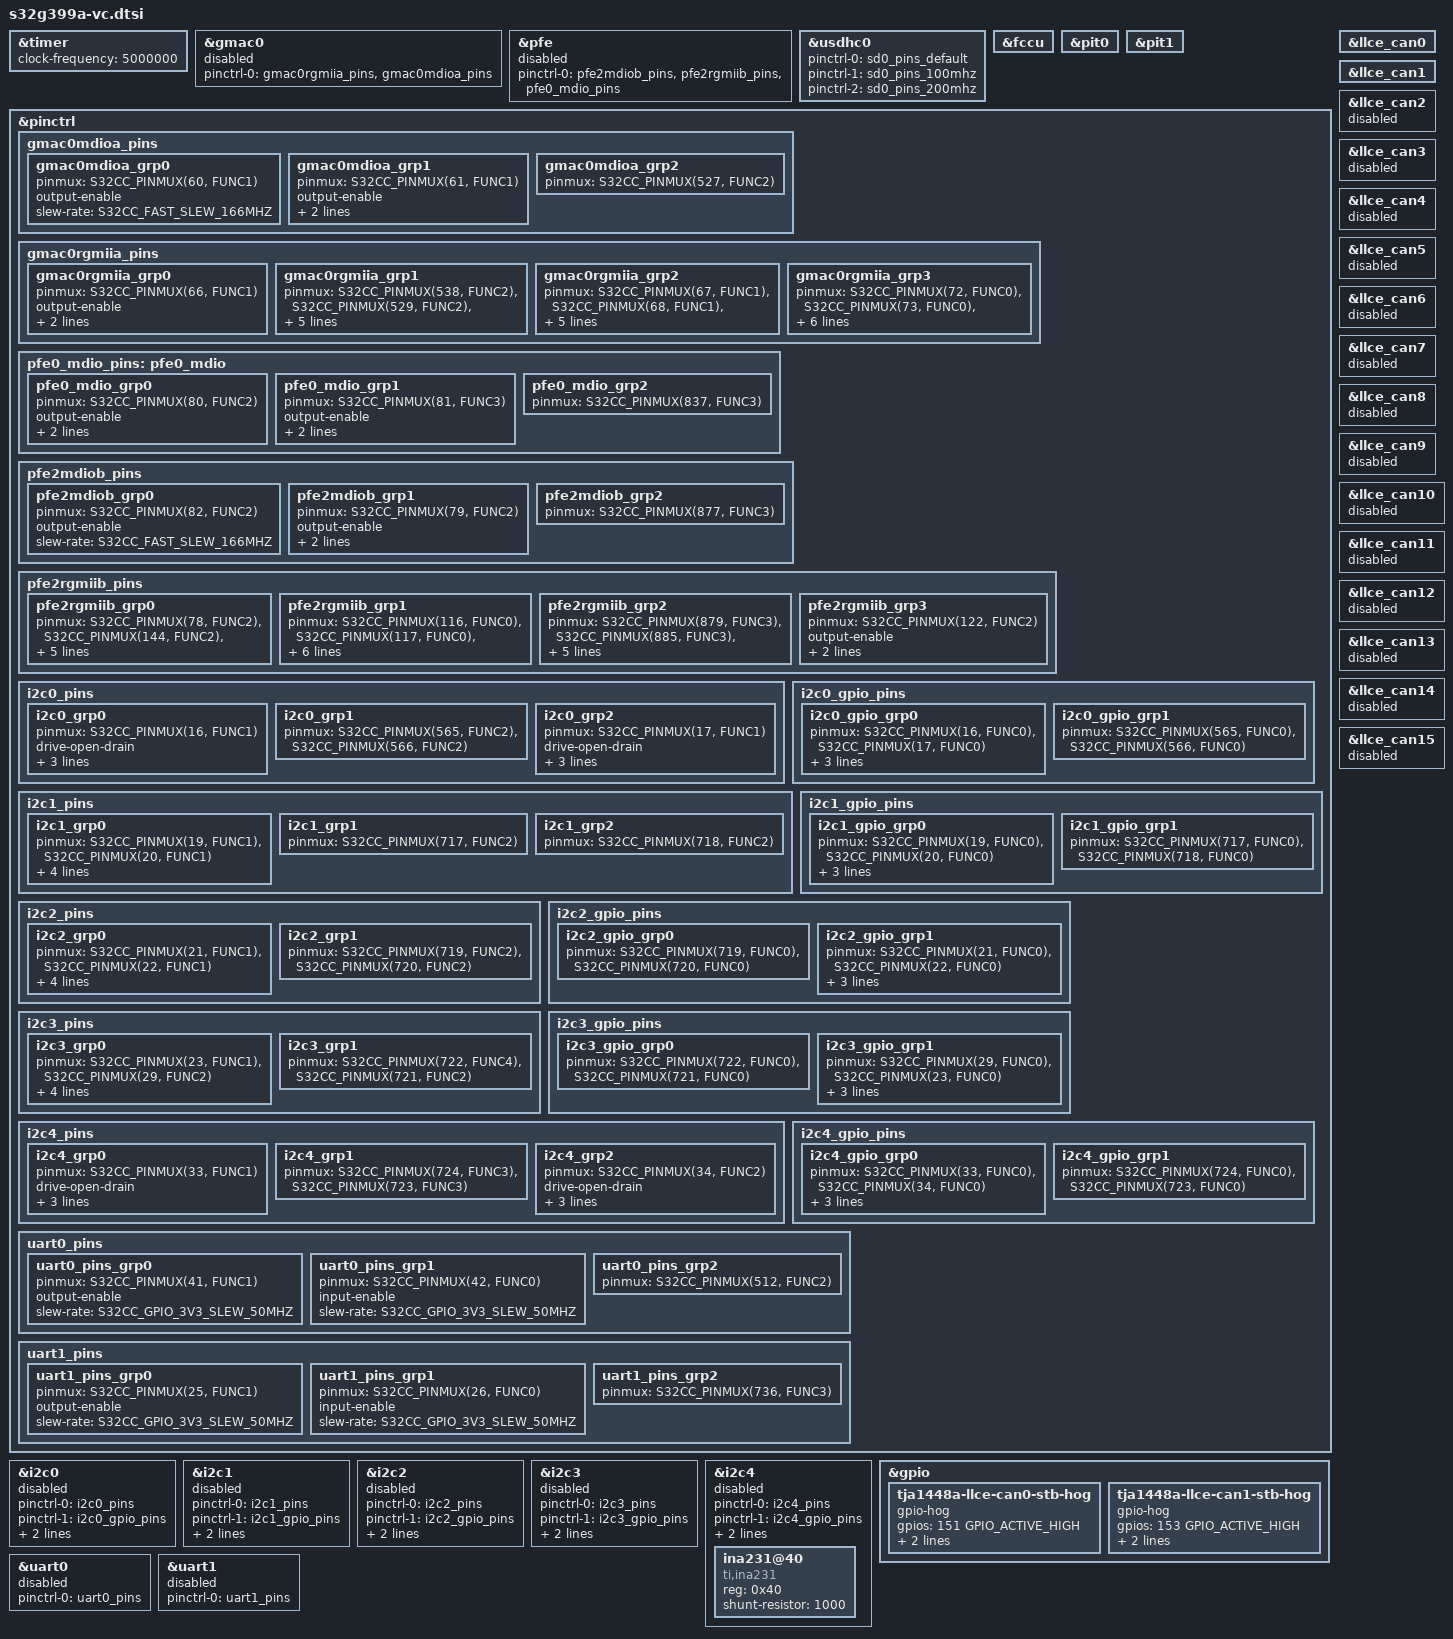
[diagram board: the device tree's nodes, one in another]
// SPDX-License-Identifier: GPL-2.0-or-later OR BSD-3-Clause
/*
 * Copyright 2024 NXP
 */

#include <dt-bindings/gpio/gpio.h>
#include "s32g3.dtsi"
#include "s32g-nxp-flash-macronix.dtsi"

&timer {
	clock-frequency = <5000000>;
};

&gmac0 {
	status = "disabled";
	pinctrl-names = "default";
	pinctrl-0 = <&gmac0rgmiia_pins>, <&gmac0mdioa_pins>;
};

&pfe {
	status = "disabled";
	pinctrl-names = "default";
	pinctrl-0 = <&pfe2mdiob_pins>, <&pfe2rgmiib_pins>, <&pfe0_mdio_pins>;
};

&usdhc0 {
	pinctrl-names = "default", "state_100mhz", "state_200mhz";
	pinctrl-0 = <&sd0_pins_default>;
	pinctrl-1 = <&sd0_pins_100mhz>;
	pinctrl-2 = <&sd0_pins_200mhz>;
	status = "okay";
};

&fccu {
	status = "okay";
};

&pit0 {
	status = "okay";
};

&pit1 {
	status = "okay";
};

&pinctrl {
	gmac0mdioa_pins: gmac0mdioa_pins {
		gmac0mdioa_grp0 {
			pinmux = <S32CC_PINMUX(60, FUNC1)>;
			output-enable;
			slew-rate = <S32CC_FAST_SLEW_166MHZ>;
		};

		gmac0mdioa_grp1 {
			pinmux = <S32CC_PINMUX(61, FUNC1)>;
			output-enable;
			input-enable;
			slew-rate = <S32CC_FAST_SLEW_166MHZ>;
		};

		gmac0mdioa_grp2 {
			pinmux = <S32CC_PINMUX(527, FUNC2)>;
		};
	};

	gmac0rgmiia_pins: gmac0rgmiia_pins {
		gmac0rgmiia_grp0 {
			pinmux = <S32CC_PINMUX(66, FUNC1)>;
			output-enable;
			slew-rate = <S32CC_FAST_SLEW_166MHZ>;
			bias-pull-up;
		};

		gmac0rgmiia_grp1 {
			pinmux = <S32CC_PINMUX(538, FUNC2)>,
				 <S32CC_PINMUX(529, FUNC2)>,
				 <S32CC_PINMUX(530, FUNC2)>,
				 <S32CC_PINMUX(531, FUNC2)>,
				 <S32CC_PINMUX(532, FUNC2)>,
				 <S32CC_PINMUX(533, FUNC2)>,
				 <S32CC_PINMUX(534, FUNC2)>;
		};

		gmac0rgmiia_grp2 {
			pinmux = <S32CC_PINMUX(67, FUNC1)>,
				 <S32CC_PINMUX(68, FUNC1)>,
				 <S32CC_PINMUX(69, FUNC1)>,
				 <S32CC_PINMUX(70, FUNC1)>,
				 <S32CC_PINMUX(71, FUNC1)>;
			output-enable;
			slew-rate = <S32CC_FAST_SLEW_166MHZ>;
		};

		gmac0rgmiia_grp3 {
			pinmux = <S32CC_PINMUX(72, FUNC0)>,
				 <S32CC_PINMUX(73, FUNC0)>,
				 <S32CC_PINMUX(74, FUNC0)>,
				 <S32CC_PINMUX(75, FUNC0)>,
				 <S32CC_PINMUX(76, FUNC0)>,
				 <S32CC_PINMUX(77, FUNC0)>;
			input-enable;
			slew-rate = <S32CC_FAST_SLEW_166MHZ>;
		};
	};

	pfe0_mdio_pins: pfe0_mdio {
		pfe0_mdio_grp0 {
			pinmux = <S32CC_PINMUX(80, FUNC2)>;
			output-enable;
			drive-push-pull;
			slew-rate = <S32CC_FAST_SLEW_166MHZ>;
		};

		pfe0_mdio_grp1 {
			pinmux = <S32CC_PINMUX(81, FUNC3)>;
			output-enable;
			input-enable;
			slew-rate = <S32CC_FAST_SLEW_166MHZ>;
		};

		pfe0_mdio_grp2 {
			pinmux = <S32CC_PINMUX(837, FUNC3)>;
		};
	};

	pfe2mdiob_pins: pfe2mdiob_pins {
		pfe2mdiob_grp0 {
			pinmux = <S32CC_PINMUX(82, FUNC2)>;
			output-enable;
			slew-rate = <S32CC_FAST_SLEW_166MHZ>;
		};

		pfe2mdiob_grp1 {
			pinmux = <S32CC_PINMUX(79, FUNC2)>;
			output-enable;
			input-enable;
			slew-rate = <S32CC_FAST_SLEW_166MHZ>;
		};

		pfe2mdiob_grp2 {
			pinmux = <S32CC_PINMUX(877, FUNC3)>;
		};
	};

	pfe2rgmiib_pins: pfe2rgmiib_pins {
		pfe2rgmiib_grp0 {
			pinmux = <S32CC_PINMUX(78, FUNC2)>,
				 <S32CC_PINMUX(144, FUNC2)>,
				 <S32CC_PINMUX(113, FUNC2)>,
				 <S32CC_PINMUX(114, FUNC2)>,
				 <S32CC_PINMUX(115, FUNC2)>;
			output-enable;
			slew-rate = <S32CC_FAST_SLEW_166MHZ>;
		};

		pfe2rgmiib_grp1 {
			pinmux = <S32CC_PINMUX(116, FUNC0)>,
				 <S32CC_PINMUX(117, FUNC0)>,
				 <S32CC_PINMUX(118, FUNC0)>,
				 <S32CC_PINMUX(119, FUNC0)>,
				 <S32CC_PINMUX(120, FUNC0)>,
				 <S32CC_PINMUX(121, FUNC0)>;
			input-enable;
			slew-rate = <S32CC_FAST_SLEW_166MHZ>;
		};

		pfe2rgmiib_grp2 {
			pinmux = <S32CC_PINMUX(879, FUNC3)>,
				 <S32CC_PINMUX(885, FUNC3)>,
				 <S32CC_PINMUX(881, FUNC3)>,
				 <S32CC_PINMUX(882, FUNC3)>,
				 <S32CC_PINMUX(883, FUNC3)>,
				 <S32CC_PINMUX(884, FUNC3)>,
				 <S32CC_PINMUX(886, FUNC3)>;
		};

		pfe2rgmiib_grp3 {
			pinmux = <S32CC_PINMUX(122, FUNC2)>;
			output-enable;
			slew-rate = <S32CC_FAST_SLEW_166MHZ>;
			bias-pull-up;
		};
	};

	i2c0_pins: i2c0_pins {
		i2c0_grp0 {
			pinmux = <S32CC_PINMUX(16, FUNC1)>;
			drive-open-drain;
			output-enable;
			input-enable;
			slew-rate = <S32CC_GPIO_3V3_SLEW_50MHZ>;
		};

		i2c0_grp1 {
			pinmux = <S32CC_PINMUX(565, FUNC2)>,
				 <S32CC_PINMUX(566, FUNC2)>;
		};

		i2c0_grp2 {
			pinmux = <S32CC_PINMUX(17, FUNC1)>;
			drive-open-drain;
			output-enable;
			input-enable;
			slew-rate = <S32CC_GPIO_3V3_SLEW_50MHZ>;
		};
	};

	i2c0_gpio_pins: i2c0_gpio_pins {
		i2c0_gpio_grp0 {
			pinmux = <S32CC_PINMUX(16, FUNC0)>,
				 <S32CC_PINMUX(17, FUNC0)>;
			drive-open-drain;
			output-enable;
			slew-rate = <S32CC_GPIO_3V3_SLEW_50MHZ>;
		};

		i2c0_gpio_grp1 {
			pinmux = <S32CC_PINMUX(565, FUNC0)>,
				 <S32CC_PINMUX(566, FUNC0)>;
		};
	};

	i2c1_pins: i2c1_pins {
		i2c1_grp0 {
			pinmux = <S32CC_PINMUX(19, FUNC1)>,
				 <S32CC_PINMUX(20, FUNC1)>;
			drive-open-drain;
			output-enable;
			input-enable;
			slew-rate = <S32CC_GPIO_3V3_SLEW_50MHZ>;
		};

		i2c1_grp1 {
			pinmux = <S32CC_PINMUX(717, FUNC2)>;
		};

		i2c1_grp2 {
			pinmux = <S32CC_PINMUX(718, FUNC2)>;
		};
	};

	i2c1_gpio_pins: i2c1_gpio_pins {
		i2c1_gpio_grp0 {
			pinmux = <S32CC_PINMUX(19, FUNC0)>,
				 <S32CC_PINMUX(20, FUNC0)>;
			drive-open-drain;
			output-enable;
			slew-rate = <S32CC_GPIO_3V3_SLEW_50MHZ>;
		};

		i2c1_gpio_grp1 {
			pinmux = <S32CC_PINMUX(717, FUNC0)>,
				 <S32CC_PINMUX(718, FUNC0)>;
		};
	};

	i2c2_pins: i2c2_pins {
		i2c2_grp0 {
			pinmux = <S32CC_PINMUX(21, FUNC1)>,
				 <S32CC_PINMUX(22, FUNC1)>;
			drive-open-drain;
			output-enable;
			input-enable;
			slew-rate = <S32CC_GPIO_3V3_SLEW_50MHZ>;
		};

		i2c2_grp1 {
			pinmux = <S32CC_PINMUX(719, FUNC2)>,
				 <S32CC_PINMUX(720, FUNC2)>;
		};
	};

	i2c2_gpio_pins: i2c2_gpio_pins {
		i2c2_gpio_grp0 {
			pinmux = <S32CC_PINMUX(719, FUNC0)>,
				 <S32CC_PINMUX(720, FUNC0)>;
		};

		i2c2_gpio_grp1 {
			pinmux = <S32CC_PINMUX(21, FUNC0)>,
				 <S32CC_PINMUX(22, FUNC0)>;
			drive-open-drain;
			output-enable;
			slew-rate = <S32CC_GPIO_3V3_SLEW_50MHZ>;
		};
	};

	i2c3_pins: i2c3_pins {
		i2c3_grp0 {
			pinmux = <S32CC_PINMUX(23, FUNC1)>,
				 <S32CC_PINMUX(29, FUNC2)>;
			drive-open-drain;
			output-enable;
			input-enable;
			slew-rate = <S32CC_GPIO_3V3_SLEW_50MHZ>;
		};

		i2c3_grp1 {
			pinmux = <S32CC_PINMUX(722, FUNC4)>,
				 <S32CC_PINMUX(721, FUNC2)>;
		};
	};

	i2c3_gpio_pins: i2c3_gpio_pins {
		i2c3_gpio_grp0 {
			pinmux = <S32CC_PINMUX(722, FUNC0)>,
				 <S32CC_PINMUX(721, FUNC0)>;
		};

		i2c3_gpio_grp1 {
			pinmux = <S32CC_PINMUX(29, FUNC0)>,
				 <S32CC_PINMUX(23, FUNC0)>;
			drive-open-drain;
			output-enable;
			slew-rate = <S32CC_GPIO_3V3_SLEW_50MHZ>;
		};
	};

	i2c4_pins: i2c4_pins {
		i2c4_grp0 {
			pinmux = <S32CC_PINMUX(33, FUNC1)>;
			drive-open-drain;
			output-enable;
			input-enable;
			slew-rate = <S32CC_GPIO_3V3_SLEW_50MHZ>;
		};

		i2c4_grp1 {
			pinmux = <S32CC_PINMUX(724, FUNC3)>,
				 <S32CC_PINMUX(723, FUNC3)>;
		};

		i2c4_grp2 {
			pinmux = <S32CC_PINMUX(34, FUNC2)>;
			drive-open-drain;
			output-enable;
			input-enable;
			slew-rate = <S32CC_GPIO_3V3_SLEW_50MHZ>;
		};
	};

	i2c4_gpio_pins: i2c4_gpio_pins {
		i2c4_gpio_grp0 {
			pinmux = <S32CC_PINMUX(33, FUNC0)>,
				 <S32CC_PINMUX(34, FUNC0)>;
			drive-open-drain;
			output-enable;
			slew-rate = <S32CC_GPIO_3V3_SLEW_50MHZ>;
		};

		i2c4_gpio_grp1 {
			pinmux = <S32CC_PINMUX(724, FUNC0)>,
				 <S32CC_PINMUX(723, FUNC0)>;
		};
	};

	uart0_pins: uart0_pins {
		uart0_pins_grp0 {
			pinmux = <S32CC_PINMUX(41, FUNC1)>;
			output-enable;
			slew-rate = <S32CC_GPIO_3V3_SLEW_50MHZ>;
		};

		uart0_pins_grp1 {
			pinmux = <S32CC_PINMUX(42, FUNC0)>;
			input-enable;
			slew-rate = <S32CC_GPIO_3V3_SLEW_50MHZ>;
		};

		uart0_pins_grp2 {
			pinmux = <S32CC_PINMUX(512, FUNC2)>;
		};
	};

	uart1_pins: uart1_pins {
		uart1_pins_grp0 {
			pinmux = <S32CC_PINMUX(25, FUNC1)>;
			output-enable;
			slew-rate = <S32CC_GPIO_3V3_SLEW_50MHZ>;
		};

		uart1_pins_grp1 {
			pinmux = <S32CC_PINMUX(26, FUNC0)>;
			input-enable;
			slew-rate = <S32CC_GPIO_3V3_SLEW_50MHZ>;
		};

		uart1_pins_grp2 {
			pinmux = <S32CC_PINMUX(736, FUNC3)>;
		};
	};
};

&i2c0 {
	pinctrl-names = "default", "gpio";
	pinctrl-0 = <&i2c0_pins>;
	pinctrl-1 = <&i2c0_gpio_pins>;
	scl-gpios = <&gpio 17 (GPIO_ACTIVE_HIGH | GPIO_OPEN_DRAIN)>;
	sda-gpios = <&gpio 16 (GPIO_ACTIVE_HIGH | GPIO_OPEN_DRAIN)>;
	status = "disabled";
};

&i2c1 {
	pinctrl-names = "default", "gpio";
	pinctrl-0 = <&i2c1_pins>;
	pinctrl-1 = <&i2c1_gpio_pins>;
	scl-gpios = <&gpio 19 (GPIO_ACTIVE_HIGH | GPIO_OPEN_DRAIN)>;
	sda-gpios = <&gpio 20 (GPIO_ACTIVE_HIGH | GPIO_OPEN_DRAIN)>;
	status = "disabled";
};

&i2c2 {
	pinctrl-names = "default", "gpio";
	pinctrl-0 = <&i2c2_pins>;
	pinctrl-1 = <&i2c2_gpio_pins>;
	scl-gpios = <&gpio 21 (GPIO_ACTIVE_HIGH | GPIO_OPEN_DRAIN)>;
	sda-gpios = <&gpio 22 (GPIO_ACTIVE_HIGH | GPIO_OPEN_DRAIN)>;
	status = "disabled";
};

&i2c3 {
	pinctrl-names = "default", "gpio";
	pinctrl-0 = <&i2c3_pins>;
	pinctrl-1 = <&i2c3_gpio_pins>;
	scl-gpios = <&gpio 23 (GPIO_ACTIVE_HIGH | GPIO_OPEN_DRAIN)>;
	sda-gpios = <&gpio 29 (GPIO_ACTIVE_HIGH | GPIO_OPEN_DRAIN)>;
	status = "disabled";
};

&i2c4 {
	pinctrl-names = "default", "gpio";
	pinctrl-0 = <&i2c4_pins>;
	pinctrl-1 = <&i2c4_gpio_pins>;
	scl-gpios = <&gpio 34 (GPIO_ACTIVE_HIGH | GPIO_OPEN_DRAIN)>;
	sda-gpios = <&gpio 33 (GPIO_ACTIVE_HIGH | GPIO_OPEN_DRAIN)>;
	status = "disabled";

	ina231@40 {
		compatible = "ti,ina231";
		reg = <0x40>;
		shunt-resistor = <1000>;
	};
};

&gpio {
	/*
	 * Drive GPIO[151] low for LLCE_CAN0 enablement.
	 */
	tja1448a-llce-can0-stb-hog {
		gpio-hog;
		gpios = <151 GPIO_ACTIVE_HIGH>;
		output-low;
		line-name = "tja1448a-llce-can0-stb";
	};

	/*
	 * Drive GPIO[153] low for LLCE_CAN1 enablement.
	 */
	tja1448a-llce-can1-stb-hog {
		gpio-hog;
		gpios = <153 GPIO_ACTIVE_HIGH>;
		output-low;
		line-name = "tja1448a-llce-can1-stb";
	};
};

/*
 * LLCE CAN 0 is connected to the JP1 connector
 * available on the S32G3-VC-SOM board.
 */
&llce_can0 {
	status = "okay";
};

/*
 * LLCE CAN 1 is connected to the JP1 connector
 * available on the S32G3-VC-SOM board.
 */
&llce_can1 {
	status = "okay";
};

&llce_can2 {
	status = "disabled";
};

&llce_can3 {
	status = "disabled";
};

&llce_can4 {
	status = "disabled";
};

&llce_can5 {
	status = "disabled";
};

&llce_can6 {
	status = "disabled";
};

&llce_can7 {
	status = "disabled";
};

&llce_can8 {
	status = "disabled";
};

&llce_can9 {
	status = "disabled";
};

&llce_can10 {
	status = "disabled";
};

&llce_can11 {
	status = "disabled";
};

&llce_can12 {
	status = "disabled";
};

&llce_can13 {
	status = "disabled";
};

&llce_can14 {
	status = "disabled";
};

&llce_can15 {
	status = "disabled";
};

&uart0 {
	status = "disabled";
	pinctrl-0 = <&uart0_pins>;
	pinctrl-names = "default";
};

&uart1 {
	status = "disabled";
	pinctrl-0 = <&uart1_pins>;
	pinctrl-names = "default";
};
